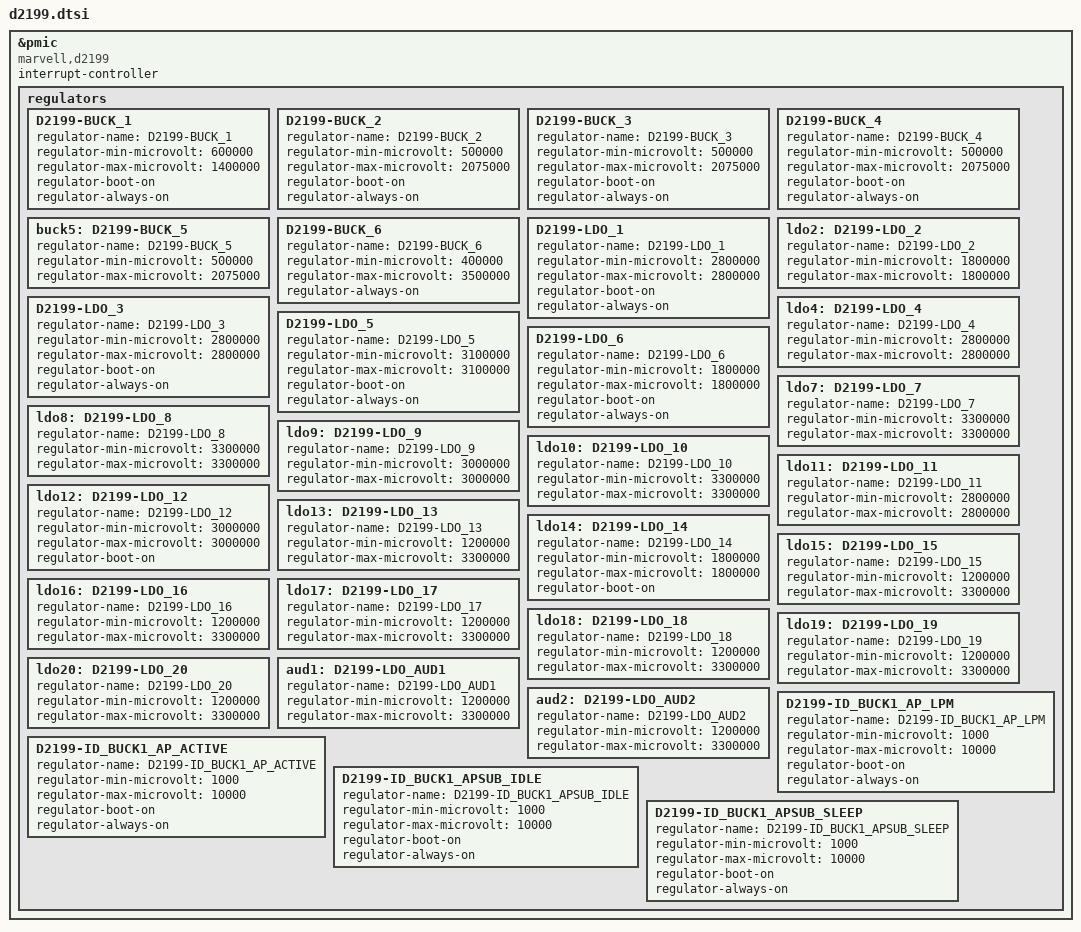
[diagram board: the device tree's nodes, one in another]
/* arch/arm/boot/dts/d2199.dtsi
 * Copyright (C) 2013 Samsung Electronics Co, Ltd.
 *
 * Based on arch/arm/boot/dts/pxa1L88dkb.dts
 * Author: Vishwanatha HG <vishwa.hg@samsung.com>
 * Author: Saurabh Singh <saurabh1.s@samsung.com>
 *
 * This software is licensed under the terms of the GNU General Public
 * License version 2, as published by the Free Software Foundation,
 * and may be copied, distributed, and modified under those terms.
 *
 * This program is distributed in the hope that it will be useful,
 * but WITHOUT ANY WARRANTY; without even the implied warranty of
 * MERCHANTABILITY or FITNESS FOR A PARTICULAR PURPOSE. See the
 * GNU General Public License for more details.
 */

/*
 * Integrated Power Management Chip from Dailog Semiconductor
 */
&pmic {
	compatible = "marvell,d2199";
	interrupt-controller;
	#interrupt-cells = <1>;
	regulators {
		D2199-BUCK_1 {
				regulator-name = "D2199-BUCK_1";
				regulator-min-microvolt = <600000>;
				regulator-max-microvolt = <1400000>;
				regulator-boot-on;
				regulator-always-on;
				};
		D2199-BUCK_2 {
				regulator-name = "D2199-BUCK_2";
				regulator-min-microvolt = <500000>;
				regulator-max-microvolt = <2075000>;
				regulator-boot-on;
				regulator-always-on;
					};
		D2199-BUCK_3 {
				regulator-name = "D2199-BUCK_3";
				regulator-min-microvolt = <500000>;
				regulator-max-microvolt = <2075000>;
				regulator-boot-on;
				regulator-always-on;
				};
		D2199-BUCK_4 {
				regulator-name = "D2199-BUCK_4";
				regulator-min-microvolt = <500000>;
				regulator-max-microvolt = <2075000>;
				regulator-boot-on;
				regulator-always-on;
				};
		buck5:D2199-BUCK_5 {
				regulator-name = "D2199-BUCK_5";
				regulator-min-microvolt = <500000>;
				regulator-max-microvolt = <2075000>;
				};
		D2199-BUCK_6 {
				regulator-name = "D2199-BUCK_6";
				regulator-min-microvolt = <400000>;
				regulator-max-microvolt = <3500000>;
				regulator-always-on;
				};
		D2199-LDO_1 {
				regulator-name = "D2199-LDO_1";
				regulator-min-microvolt = <2800000>;
				regulator-max-microvolt = <2800000>;
				regulator-boot-on;
				regulator-always-on;
				};
		ldo2:D2199-LDO_2 {
				regulator-name = "D2199-LDO_2";
				regulator-min-microvolt = <1800000>;
				regulator-max-microvolt = <1800000>;
				};
		D2199-LDO_3 {
				regulator-name = "D2199-LDO_3";
				regulator-min-microvolt = <2800000>;
				regulator-max-microvolt = <2800000>;
				regulator-boot-on;
				regulator-always-on;
				};
		ldo4:D2199-LDO_4 {
				regulator-name = "D2199-LDO_4";
				regulator-min-microvolt = <2800000>;
				regulator-max-microvolt = <2800000>;
				};
		D2199-LDO_5  {
				regulator-name = "D2199-LDO_5";
				regulator-min-microvolt = <3100000>;
				regulator-max-microvolt = <3100000>;
				regulator-boot-on;
				regulator-always-on;
				};
		D2199-LDO_6 {
				regulator-name = "D2199-LDO_6";
				regulator-min-microvolt = <1800000>;
				regulator-max-microvolt = <1800000>;
				regulator-boot-on;
				regulator-always-on;
				};
		ldo7:D2199-LDO_7 {
				regulator-name = "D2199-LDO_7";
				regulator-min-microvolt = <3300000>;
				regulator-max-microvolt = <3300000>;
				};
		ldo8:D2199-LDO_8 {
				regulator-name = "D2199-LDO_8";
				regulator-min-microvolt = <3300000>;
				regulator-max-microvolt = <3300000>;
				};
		ldo9:D2199-LDO_9 {
				regulator-name = "D2199-LDO_9";
				regulator-min-microvolt = <3000000>;
				regulator-max-microvolt = <3000000>;
				};
		ldo10:D2199-LDO_10 {
				regulator-name = "D2199-LDO_10";
				regulator-min-microvolt = <3300000>;
				regulator-max-microvolt = <3300000>;
				};
		ldo11:D2199-LDO_11 {
				regulator-name = "D2199-LDO_11";
				regulator-min-microvolt = <2800000>;
				regulator-max-microvolt = <2800000>;
				};
		ldo12:D2199-LDO_12 {
				regulator-name = "D2199-LDO_12";
				regulator-min-microvolt = <3000000>;
				regulator-max-microvolt = <3000000>;
				regulator-boot-on;
				};
		ldo13:D2199-LDO_13 {
				regulator-name = "D2199-LDO_13";
				regulator-min-microvolt = <1200000>;
				regulator-max-microvolt = <3300000>;
				};
		ldo14:D2199-LDO_14 {
				regulator-name = "D2199-LDO_14";
				regulator-min-microvolt = <1800000>;
				regulator-max-microvolt = <1800000>;
				regulator-boot-on;
				};
		ldo15:D2199-LDO_15 {
				regulator-name = "D2199-LDO_15";
				regulator-min-microvolt = <1200000>;
				regulator-max-microvolt = <3300000>;
				};
		ldo16:D2199-LDO_16 {
				regulator-name = "D2199-LDO_16";
				regulator-min-microvolt = <1200000>;
				regulator-max-microvolt = <3300000>;
				};
		ldo17:D2199-LDO_17 {
				regulator-name = "D2199-LDO_17";
				regulator-min-microvolt = <1200000>;
				regulator-max-microvolt = <3300000>;
				};
		ldo18:D2199-LDO_18 {
				regulator-name = "D2199-LDO_18";
				regulator-min-microvolt = <1200000>;
				regulator-max-microvolt = <3300000>;
				};
		ldo19:D2199-LDO_19 {
				regulator-name = "D2199-LDO_19";
				regulator-min-microvolt = <1200000>;
				regulator-max-microvolt = <3300000>;
				};
		ldo20:D2199-LDO_20 {
				regulator-name = "D2199-LDO_20";
				regulator-min-microvolt = <1200000>;
				regulator-max-microvolt = <3300000>;
				};
		aud1:D2199-LDO_AUD1 {
				regulator-name = "D2199-LDO_AUD1";
				regulator-min-microvolt = <1200000>;
				regulator-max-microvolt = <3300000>;
				};
		aud2:D2199-LDO_AUD2 {
				regulator-name = "D2199-LDO_AUD2";
				regulator-min-microvolt = <1200000>;
				regulator-max-microvolt = <3300000>;
				};
		D2199-ID_BUCK1_AP_ACTIVE {
				regulator-name = "D2199-ID_BUCK1_AP_ACTIVE";
				regulator-min-microvolt = <1000>;
				regulator-max-microvolt = <10000>;
				regulator-boot-on;
				regulator-always-on;
				};
		D2199-ID_BUCK1_AP_LPM {
				regulator-name = "D2199-ID_BUCK1_AP_LPM";
				regulator-min-microvolt = <1000>;
				regulator-max-microvolt = <10000>;
				regulator-boot-on;
				regulator-always-on;
				};
		D2199-ID_BUCK1_APSUB_IDLE {
				regulator-name = "D2199-ID_BUCK1_APSUB_IDLE";
				regulator-min-microvolt = <1000>;
				regulator-max-microvolt = <10000>;
				regulator-boot-on;
				regulator-always-on;
				};
		D2199-ID_BUCK1_APSUB_SLEEP {
				regulator-name = "D2199-ID_BUCK1_APSUB_SLEEP";
				regulator-min-microvolt = <1000>;
				regulator-max-microvolt = <10000>;
				regulator-boot-on;
				regulator-always-on;
				};
	};
};
